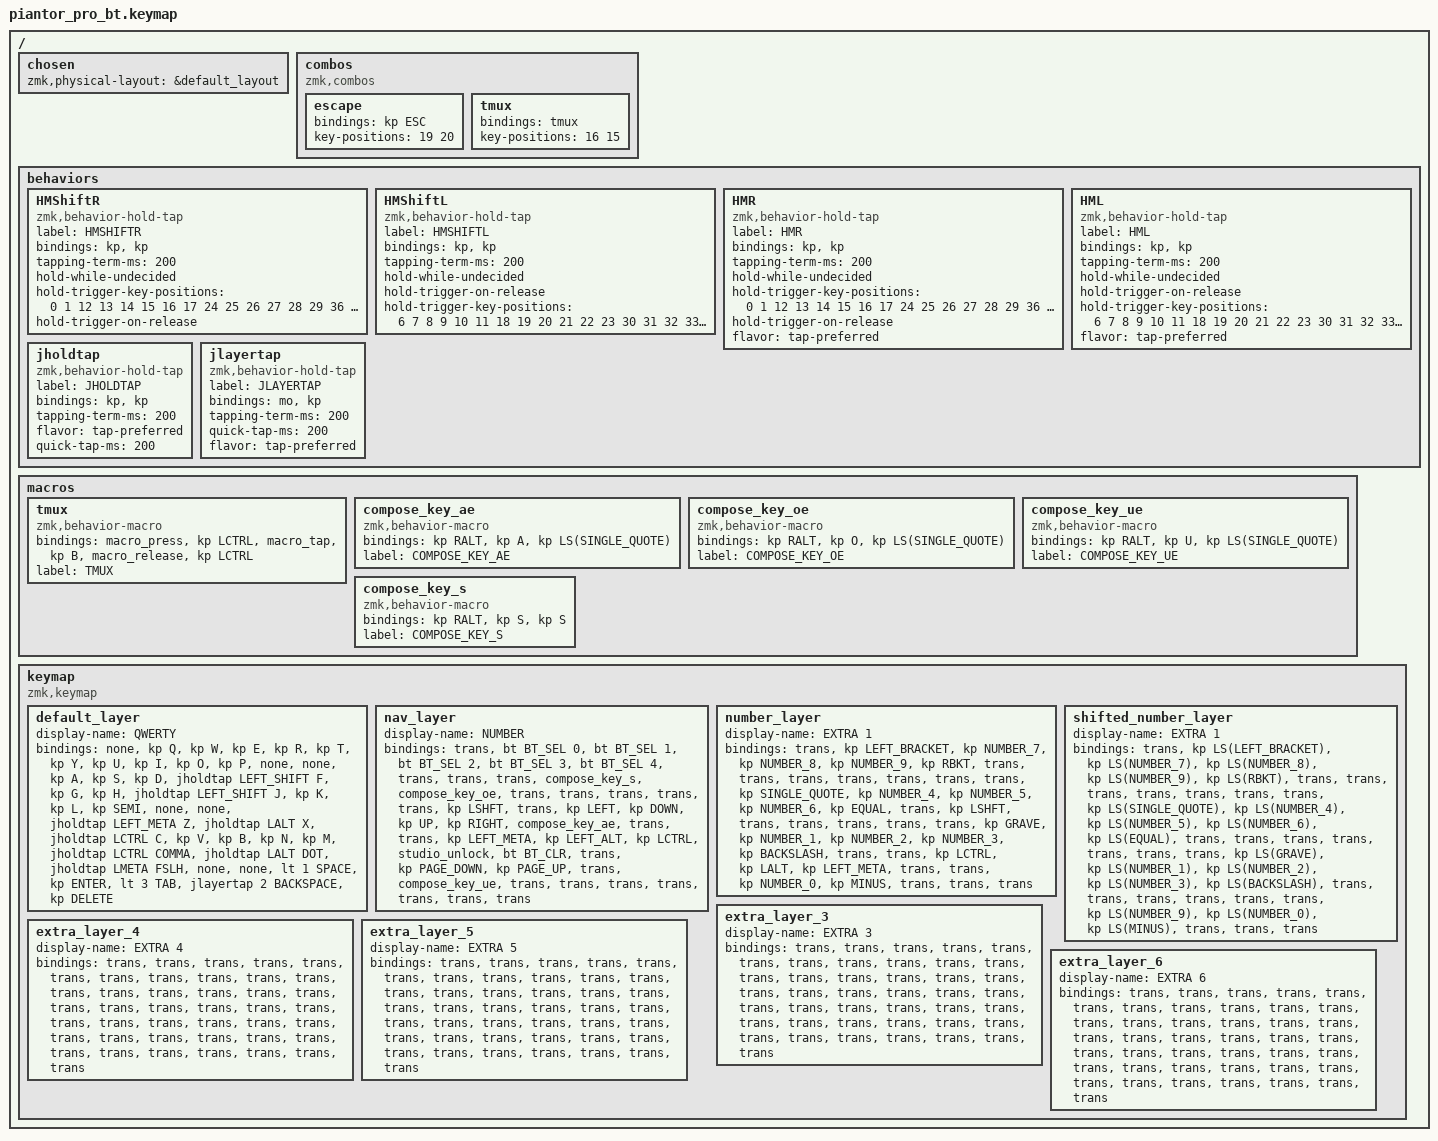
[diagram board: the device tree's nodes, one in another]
/*
 * Copyright (c) 2020 The ZMK Contributors
 *
 * SPDX-License-Identifier: MIT
 */

#include <behaviors.dtsi>
#include <dt-bindings/zmk/bt.h>
#include <dt-bindings/zmk/keys.h>

/ {
    chosen { zmk,physical-layout = &default_layout; };
};

/ {
    combos {
        compatible = "zmk,combos";

        escape {
            bindings = <&kp ESC>;
            key-positions = <19 20>;
        };

        tmux {
            bindings = <&tmux>;
            key-positions = <16 15>;
        };
    };

    behaviors {
        HMShiftR: HMShiftR {
            compatible = "zmk,behavior-hold-tap";
            label = "HMSHIFTR";
            bindings = <&kp>, <&kp>;

            #binding-cells = <2>;
            tapping-term-ms = <200>;
            hold-while-undecided;
            hold-trigger-key-positions = <0 1 12 13 14 15 16 17 24 25 26 27 28 29 36 37 38 2 3 4 5>;
            hold-trigger-on-release;
        };

        HMShiftL: HMShiftL {
            compatible = "zmk,behavior-hold-tap";
            label = "HMSHIFTL";
            bindings = <&kp>, <&kp>;

            #binding-cells = <2>;
            tapping-term-ms = <200>;
            hold-while-undecided;
            hold-trigger-on-release;
            hold-trigger-key-positions = <6 7 8 9 10 11 18 19 20 21 22 23 30 31 32 33 34 35 39 40 41>;
        };

        HMR: HMR {
            compatible = "zmk,behavior-hold-tap";
            label = "HMR";
            bindings = <&kp>, <&kp>;

            #binding-cells = <2>;
            tapping-term-ms = <200>;
            hold-while-undecided;
            hold-trigger-key-positions = <0 1 12 13 14 15 16 17 24 25 26 27 28 29 36 37 38 2 3 4 5>;
            hold-trigger-on-release;
            flavor = "tap-preferred";
        };

        HML: HML {
            compatible = "zmk,behavior-hold-tap";
            label = "HML";
            bindings = <&kp>, <&kp>;

            #binding-cells = <2>;
            tapping-term-ms = <200>;
            hold-while-undecided;
            hold-trigger-on-release;
            hold-trigger-key-positions = <6 7 8 9 10 11 18 19 20 21 22 23 30 31 32 33 34 35 39 40 41>;
            flavor = "tap-preferred";
        };

        jholdtap: jholdtap {
            compatible = "zmk,behavior-hold-tap";
            label = "JHOLDTAP";
            bindings = <&kp>, <&kp>;

            #binding-cells = <2>;
            tapping-term-ms = <200>;
            flavor = "tap-preferred";
            quick-tap-ms = <200>;
        };

        jlayertap: jlayertap {
            compatible = "zmk,behavior-hold-tap";
            label = "JLAYERTAP";
            bindings = <&mo>, <&kp>;

            #binding-cells = <2>;
            tapping-term-ms = <200>;
            quick-tap-ms = <200>;
            flavor = "tap-preferred";
        };
    };

    macros {
        tmux: tmux {
            compatible = "zmk,behavior-macro";
            #binding-cells = <0>;
            bindings =
                <&macro_press>,
                <&kp LCTRL>,
                <&macro_tap>,
                <&kp B>,
                <&macro_release>,
                <&kp LCTRL>;

            label = "TMUX";
        };

        compose_key_ae: compose_key_ae {
            compatible = "zmk,behavior-macro";
            #binding-cells = <0>;
            bindings = <&kp RALT &kp A &kp LS(SINGLE_QUOTE)>;
            label = "COMPOSE_KEY_AE";
        };

        compose_key_oe: compose_key_oe {
            compatible = "zmk,behavior-macro";
            #binding-cells = <0>;
            bindings = <&kp RALT &kp O &kp LS(SINGLE_QUOTE)>;
            label = "COMPOSE_KEY_OE";
        };

        compose_key_ue: compose_key_ue {
            compatible = "zmk,behavior-macro";
            #binding-cells = <0>;
            bindings = <&kp RALT &kp U &kp LS(SINGLE_QUOTE)>;
            label = "COMPOSE_KEY_UE";
        };

        compose_key_s: compose_key_s {
            compatible = "zmk,behavior-macro";
            #binding-cells = <0>;
            bindings = <&kp RALT &kp S &kp S>;
            label = "COMPOSE_KEY_S";
        };
    };

    keymap {
        compatible = "zmk,keymap";

        default_layer {
            display-name = "QWERTY";

            // --------------------------------------------------------------------------------
            // |  TAB |  Q  |  W  |  E  |  R  |  T  |  Y  |  U   |  I  |  O  |  P  | BSPC |
            // | CTRL |  A  |  S  |  D  |  F  |  G  |  H  |  J   |  K  |  L  |  ;  |  '   |
            // | SHFT |  Z  |  X  |  C  |  V  |  B  |  N  |  M   |  ,  |  .  |  /  | ESC  |
            //                    | GUI | LWR | SPC | ENT | RSE  | ALT |

            bindings = <
&none  &kp Q  &kp W  &kp E  &kp R  &kp T  &kp Y  &kp U  &kp I  &kp O  &kp P  &none  &none  &kp A  &kp S  &kp D  &jholdtap LEFT_SHIFT F  &kp G  &kp H  &jholdtap LEFT_SHIFT J  &kp K  &kp L  &kp SEMI  &none  &none  &jholdtap LEFT_META Z  &jholdtap LALT X  &jholdtap LCTRL C  &kp V  &kp B  &kp N  &kp M  &jholdtap LCTRL COMMA  &jholdtap LALT DOT  &jholdtap LMETA FSLH  &none  &none  &lt 1 SPACE  &kp ENTER  &lt 3 TAB  &jlayertap 2 BACKSPACE  &kp DELETE
            >;
        };

        nav_layer {
            display-name = "NUMBER";

            // -----------------------------------------------------------------------------------------
            // |  TAB |  1  |  2  |  3  |  4  |  5    |  6  |  7  |  8  |  9  |  0  | BSPC |
            // | CTRL | BT1 | BT2 | BT3 | BT4 | BT5   | LFT | DWN |  UP | RGT |     |      |
            // | SHFT | BTCR| RGB | RST | BOOT| Unlock|     |     |     |     |     |      |
            //                    | GUI |     | SPC   | ENT |     | ALT |

            bindings = <
&trans  &bt BT_SEL 0  &bt BT_SEL 1  &bt BT_SEL 2  &bt BT_SEL 3  &bt BT_SEL 4  &trans  &trans  &trans  &compose_key_s  &compose_key_oe  &trans  &trans  &trans  &trans  &trans  &kp LSHFT  &trans  &kp LEFT  &kp DOWN  &kp UP  &kp RIGHT  &compose_key_ae  &trans  &trans  &kp LEFT_META  &kp LEFT_ALT  &kp LCTRL  &studio_unlock  &bt BT_CLR  &trans  &kp PAGE_DOWN  &kp PAGE_UP  &trans  &compose_key_ue  &trans  &trans  &trans  &trans  &trans  &trans  &trans
            >;
        };

        number_layer {
            display-name = "EXTRA 1";
            bindings = <
&trans  &kp LEFT_BRACKET  &kp NUMBER_7  &kp NUMBER_8  &kp NUMBER_9  &kp RBKT  &trans  &trans  &trans  &trans  &trans  &trans  &trans  &kp SINGLE_QUOTE  &kp NUMBER_4  &kp NUMBER_5  &kp NUMBER_6  &kp EQUAL  &trans  &kp LSHFT  &trans  &trans  &trans  &trans  &trans  &kp GRAVE  &kp NUMBER_1  &kp NUMBER_2  &kp NUMBER_3  &kp BACKSLASH  &trans  &trans  &kp LCTRL  &kp LALT  &kp LEFT_META  &trans  &trans  &kp NUMBER_0  &kp MINUS  &trans  &trans  &trans
            >;
        };

        shifted_number_layer {
            display-name = "EXTRA 1";
            bindings = <
&trans  &kp LS(LEFT_BRACKET)  &kp LS(NUMBER_7)  &kp LS(NUMBER_8)  &kp LS(NUMBER_9)  &kp LS(RBKT)  &trans  &trans  &trans  &trans  &trans  &trans  &trans  &kp LS(SINGLE_QUOTE)  &kp LS(NUMBER_4)  &kp LS(NUMBER_5)  &kp LS(NUMBER_6)  &kp LS(EQUAL)  &trans  &trans  &trans  &trans  &trans  &trans  &trans  &kp LS(GRAVE)  &kp LS(NUMBER_1)  &kp LS(NUMBER_2)  &kp LS(NUMBER_3)  &kp LS(BACKSLASH)  &trans  &trans  &trans  &trans  &trans  &trans  &kp LS(NUMBER_9)  &kp LS(NUMBER_0)  &kp LS(MINUS)  &trans  &trans  &trans
            >;
        };

        extra_layer_3 {
            display-name = "EXTRA 3";
            bindings = <
&trans  &trans  &trans  &trans  &trans  &trans  &trans  &trans  &trans  &trans  &trans  &trans  &trans  &trans  &trans  &trans  &trans  &trans  &trans  &trans  &trans  &trans  &trans  &trans  &trans  &trans  &trans  &trans  &trans  &trans  &trans  &trans  &trans  &trans  &trans  &trans  &trans  &trans  &trans  &trans  &trans  &trans
            >;
        };

        extra_layer_4 {
            display-name = "EXTRA 4";
            bindings = <
&trans  &trans  &trans  &trans  &trans  &trans  &trans  &trans  &trans  &trans  &trans  &trans  &trans  &trans  &trans  &trans  &trans  &trans  &trans  &trans  &trans  &trans  &trans  &trans  &trans  &trans  &trans  &trans  &trans  &trans  &trans  &trans  &trans  &trans  &trans  &trans  &trans  &trans  &trans  &trans  &trans  &trans
            >;
        };

        extra_layer_5 {
            display-name = "EXTRA 5";
            bindings = <
&trans  &trans  &trans  &trans  &trans  &trans  &trans  &trans  &trans  &trans  &trans  &trans  &trans  &trans  &trans  &trans  &trans  &trans  &trans  &trans  &trans  &trans  &trans  &trans  &trans  &trans  &trans  &trans  &trans  &trans  &trans  &trans  &trans  &trans  &trans  &trans  &trans  &trans  &trans  &trans  &trans  &trans
            >;
        };

        extra_layer_6 {
            display-name = "EXTRA 6";
            bindings = <
&trans  &trans  &trans  &trans  &trans  &trans  &trans  &trans  &trans  &trans  &trans  &trans  &trans  &trans  &trans  &trans  &trans  &trans  &trans  &trans  &trans  &trans  &trans  &trans  &trans  &trans  &trans  &trans  &trans  &trans  &trans  &trans  &trans  &trans  &trans  &trans  &trans  &trans  &trans  &trans  &trans  &trans
            >;
        };
    };
};
